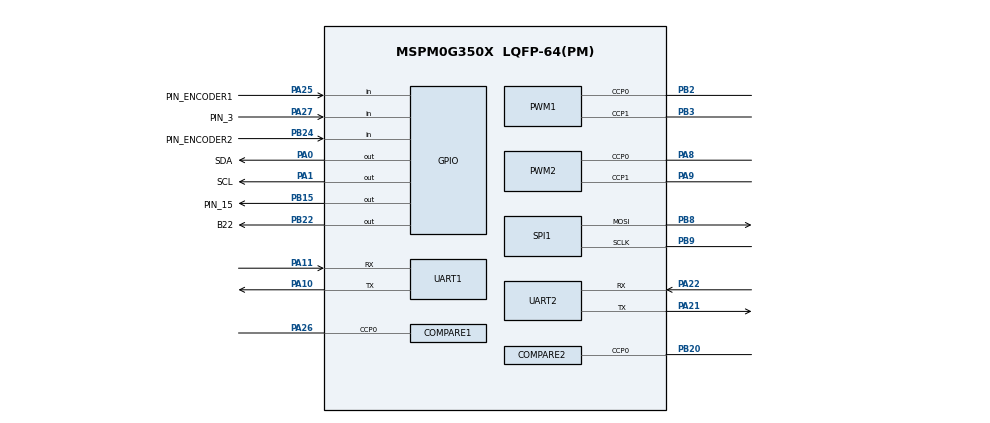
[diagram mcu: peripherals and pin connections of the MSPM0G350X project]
/**
 * @cliArgs --device "MSPM0G350X" --part "Default" --package "LQFP-64(PM)" --product "mspm0_sdk@2.02.00.05"
 * @versions {"tool":"1.21.1+3772"}
 */

/**
 * Import the modules used in this configuration.
 */
const COMPARE  = scripting.addModule("/ti/driverlib/COMPARE", {}, false);
const COMPARE1 = COMPARE.addInstance();
const COMPARE2 = COMPARE.addInstance();
const DMA      = scripting.addModule("/ti/driverlib/DMA");
const GPIO     = scripting.addModule("/ti/driverlib/GPIO", {}, false);
const GPIO1    = GPIO.addInstance();
const GPIO2    = GPIO.addInstance();
const GPIO3    = GPIO.addInstance();
const GPIO4    = GPIO.addInstance();
const GPIO5    = GPIO.addInstance();
const GPIO6    = GPIO.addInstance();
const GPIO7    = GPIO.addInstance();
const GPIO8    = GPIO.addInstance();
const PWM      = scripting.addModule("/ti/driverlib/PWM", {}, false);
const PWM1     = PWM.addInstance();
const PWM2     = PWM.addInstance();
const SPI      = scripting.addModule("/ti/driverlib/SPI", {}, false);
const SPI1     = SPI.addInstance();
const SYSCTL   = scripting.addModule("/ti/driverlib/SYSCTL");
const SYSTICK  = scripting.addModule("/ti/driverlib/SYSTICK");
const TIMER    = scripting.addModule("/ti/driverlib/TIMER", {}, false);
const TIMER1   = TIMER.addInstance();
const UART     = scripting.addModule("/ti/driverlib/UART", {}, false);
const UART1    = UART.addInstance();
const UART2    = UART.addInstance();

/**
 * Write custom configuration values to the imported modules.
 */
const divider9       = system.clockTree["UDIV"];
divider9.divideValue = 2;

const gate7  = system.clockTree["MFCLKGATE"];
gate7.enable = true;

const multiplier2         = system.clockTree["PLL_QDIV"];
multiplier2.multiplyValue = 4;

const mux4       = system.clockTree["EXHFMUX"];
mux4.inputSelect = "EXHFMUX_XTAL";

const mux8       = system.clockTree["HSCLKMUX"];
mux8.inputSelect = "HSCLKMUX_SYSPLL0";

const mux12       = system.clockTree["SYSPLLMUX"];
mux12.inputSelect = "zSYSPLLMUX_HFCLK";

const pinFunction4     = system.clockTree["HFXT"];
pinFunction4.enable    = true;
pinFunction4.inputFreq = 40;

COMPARE1.$name                              = "ENCODER1";
COMPARE1.timerPeriod                        = 65536;
COMPARE1.timerStartTimer                    = true;
COMPARE1.edgeDetection                      = "EDGE";
COMPARE1.compareMode                        = "EDGE_COUNT_UP";
COMPARE1.filterPeriod                       = "PER_8";
COMPARE1.timerClkSrc                        = "MFCLK";
COMPARE1.peripheral.$assign                 = "TIMG8";
COMPARE1.peripheral.ccp0Pin.$assign         = "PA26";
COMPARE1.ccp0PinConfig.hideOutputInversion  = scripting.forceWrite(false);
COMPARE1.ccp0PinConfig.onlyInternalResistor = scripting.forceWrite(false);
COMPARE1.ccp0PinConfig.passedPeripheralType = scripting.forceWrite("Digital");
COMPARE1.ccp0PinConfig.$name                = "ti_driverlib_gpio_GPIOPinGeneric12";
COMPARE1.ccp0PinConfig.internalResistor     = "PULL_DOWN";

const Board = scripting.addModule("/ti/driverlib/Board", {}, false);

COMPARE2.timerPeriod                        = 65536;
COMPARE2.timerStartTimer                    = true;
COMPARE2.edgeDetection                      = "EDGE";
COMPARE2.compareMode                        = "EDGE_COUNT_UP";
COMPARE2.filterPeriod                       = "PER_8";
COMPARE2.$name                              = "ENCODER2";
COMPARE2.timerClkSrc                        = "MFCLK";
COMPARE2.timerClkDiv                        = 4;
COMPARE2.peripheral.$assign                 = "TIMG12";
COMPARE2.peripheral.ccp0Pin.$assign         = "PB20";
COMPARE2.ccp0PinConfig.hideOutputInversion  = scripting.forceWrite(false);
COMPARE2.ccp0PinConfig.onlyInternalResistor = scripting.forceWrite(false);
COMPARE2.ccp0PinConfig.passedPeripheralType = scripting.forceWrite("Digital");
COMPARE2.ccp0PinConfig.$name                = "ti_driverlib_gpio_GPIOPinGeneric12_COPY";
COMPARE2.ccp0PinConfig.internalResistor     = "PULL_DOWN";

GPIO1.$name                               = "KEY";
GPIO1.port                                = "PORTB";
GPIO1.associatedPins.create(4);
GPIO1.associatedPins[0].direction         = "INPUT";
GPIO1.associatedPins[0].ioStructure       = "SD";
GPIO1.associatedPins[0].internalResistor  = "PULL_UP";
GPIO1.associatedPins[0].assignedPin       = "21";
GPIO1.associatedPins[0].polarity          = "FALL";
GPIO1.associatedPins[0].interruptEn       = true;
GPIO1.associatedPins[0].interruptPriority = "0";
GPIO1.associatedPins[0].$name             = "up";
GPIO1.associatedPins[1].direction         = "INPUT";
GPIO1.associatedPins[1].ioStructure       = "SD";
GPIO1.associatedPins[1].internalResistor  = "PULL_UP";
GPIO1.associatedPins[1].assignedPin       = "19";
GPIO1.associatedPins[1].$name             = "down";
GPIO1.associatedPins[2].direction         = "INPUT";
GPIO1.associatedPins[2].ioStructure       = "SD";
GPIO1.associatedPins[2].internalResistor  = "PULL_UP";
GPIO1.associatedPins[2].assignedPin       = "18";
GPIO1.associatedPins[2].$name             = "left";
GPIO1.associatedPins[3].direction         = "INPUT";
GPIO1.associatedPins[3].ioStructure       = "SD";
GPIO1.associatedPins[3].internalResistor  = "PULL_UP";
GPIO1.associatedPins[3].assignedPin       = "17";
GPIO1.associatedPins[3].$name             = "right";

GPIO2.$name                              = "LED";
GPIO2.port                               = "PORTB";
GPIO2.associatedPins[0].$name            = "B22";
GPIO2.associatedPins[0].ioStructure      = "SD";
GPIO2.associatedPins[0].internalResistor = "PULL_DOWN";
GPIO2.associatedPins[0].assignedPin      = "22";
GPIO2.associatedPins[0].pin.$assign      = "PB22";

GPIO3.$name                          = "LCD";
GPIO3.associatedPins.create(4);
GPIO3.associatedPins[0].ioStructure  = "SD";
GPIO3.associatedPins[0].initialValue = "SET";
GPIO3.associatedPins[0].$name        = "RES";
GPIO3.associatedPins[0].assignedPort = "PORTB";
GPIO3.associatedPins[0].assignedPin  = "10";
GPIO3.associatedPins[1].initialValue = "SET";
GPIO3.associatedPins[1].ioStructure  = "SD";
GPIO3.associatedPins[1].$name        = "DC";
GPIO3.associatedPins[1].assignedPort = "PORTB";
GPIO3.associatedPins[1].assignedPin  = "11";
GPIO3.associatedPins[2].initialValue = "SET";
GPIO3.associatedPins[2].ioStructure  = "SD";
GPIO3.associatedPins[2].$name        = "CS";
GPIO3.associatedPins[2].assignedPort = "PORTB";
GPIO3.associatedPins[2].assignedPin  = "14";
GPIO3.associatedPins[3].ioStructure  = "SD";
GPIO3.associatedPins[3].initialValue = "SET";
GPIO3.associatedPins[3].$name        = "BLK";
GPIO3.associatedPins[3].assignedPort = "PORTB";
GPIO3.associatedPins[3].assignedPin  = "26";

GPIO4.$name                          = "Gray_Address";
GPIO4.associatedPins.create(4);
GPIO4.associatedPins[0].$name        = "PIN_0";
GPIO4.associatedPins[0].assignedPort = "PORTA";
GPIO4.associatedPins[0].assignedPin  = "17";
GPIO4.associatedPins[0].direction    = "INPUT";
GPIO4.associatedPins[1].$name        = "PIN_1";
GPIO4.associatedPins[1].assignedPort = "PORTA";
GPIO4.associatedPins[1].assignedPin  = "16";
GPIO4.associatedPins[1].direction    = "INPUT";
GPIO4.associatedPins[2].$name        = "PIN_2";
GPIO4.associatedPins[2].assignedPort = "PORTA";
GPIO4.associatedPins[2].assignedPin  = "15";
GPIO4.associatedPins[2].direction    = "INPUT";
GPIO4.associatedPins[3].$name        = "PIN_3";
GPIO4.associatedPins[3].assignedPort = "PORTA";
GPIO4.associatedPins[3].assignedPin  = "27";
GPIO4.associatedPins[3].direction    = "INPUT";
GPIO4.associatedPins[3].pin.$assign  = "PA27";

GPIO5.$name                          = "IIC_Software";
GPIO5.associatedPins.create(2);
GPIO5.associatedPins[0].$name        = "SDA";
GPIO5.associatedPins[0].initialValue = "SET";
GPIO5.associatedPins[0].ioStructure  = "OD";
GPIO5.associatedPins[0].assignedPort = "PORTA";
GPIO5.associatedPins[0].assignedPin  = "0";
GPIO5.associatedPins[0].pin.$assign  = "PA0";
GPIO5.associatedPins[1].$name        = "SCL";
GPIO5.associatedPins[1].initialValue = "SET";
GPIO5.associatedPins[1].ioStructure  = "OD";
GPIO5.associatedPins[1].assignedPort = "PORTA";
GPIO5.associatedPins[1].assignedPin  = "1";
GPIO5.associatedPins[1].pin.$assign  = "PA1";

GPIO6.$name                               = "ENCODER1_DIR";
GPIO6.port                                = "PORTA";
GPIO6.associatedPins[0].$name             = "PIN_ENCODER1";
GPIO6.associatedPins[0].direction         = "INPUT";
GPIO6.associatedPins[0].interruptEn       = true;
GPIO6.associatedPins[0].interruptPriority = "1";
GPIO6.associatedPins[0].polarity          = "RISE_FALL";
GPIO6.associatedPins[0].assignedPin       = "25";
GPIO6.associatedPins[0].pin.$assign       = "PA25";

GPIO7.$name                               = "ENCODER2_DIR";
GPIO7.port                                = "PORTB";
GPIO7.associatedPins[0].$name             = "PIN_ENCODER2";
GPIO7.associatedPins[0].direction         = "INPUT";
GPIO7.associatedPins[0].interruptEn       = true;
GPIO7.associatedPins[0].polarity          = "RISE_FALL";
GPIO7.associatedPins[0].interruptPriority = "1";
GPIO7.associatedPins[0].assignedPin       = "24";
GPIO7.associatedPins[0].pin.$assign       = "PB24";

GPIO8.$name                              = "GPIO_MOS";
GPIO8.port                               = "PORTB";
GPIO8.associatedPins[0].$name            = "PIN_15";
GPIO8.associatedPins[0].internalResistor = "PULL_DOWN";
GPIO8.associatedPins[0].assignedPin      = "15";
GPIO8.associatedPins[0].pin.$assign      = "PB15";

PWM1.$name                      = "PWM_0";
PWM1.timerStartTimer            = true;
PWM1.pwmMode                    = "EDGE_ALIGN_UP";
PWM1.timerCount                 = 8000;
PWM1.peripheral.$assign         = "TIMA1";
PWM1.peripheral.ccp0Pin.$assign = "PB2";
PWM1.peripheral.ccp1Pin.$assign = "PB3";
PWM1.PWM_CHANNEL_0.$name        = "ti_driverlib_pwm_PWMTimerCC0";
PWM1.PWM_CHANNEL_1.$name        = "ti_driverlib_pwm_PWMTimerCC1";
PWM1.ccp0PinConfig.$name        = "PWM";
PWM1.ccp1PinConfig.$name        = "P";

PWM2.$name                      = "PWM_1";
PWM2.timerCount                 = 8000;
PWM2.timerStartTimer            = true;
PWM2.pwmMode                    = "EDGE_ALIGN_UP";
PWM2.peripheral.$assign         = "TIMA0";
PWM2.peripheral.ccp0Pin.$assign = "PA8";
PWM2.peripheral.ccp1Pin.$assign = "PA9";
PWM2.PWM_CHANNEL_0.$name        = "ti_driverlib_pwm_PWMTimerCC2";
PWM2.PWM_CHANNEL_1.$name        = "ti_driverlib_pwm_PWMTimerCC3";
PWM2.ccp0PinConfig.$name        = "PW";
PWM2.ccp1PinConfig.$name        = "PWM_";

SPI1.direction                          = "PICO";
SPI1.frameFormat                        = "MOTO3";
SPI1.targetBitRate                      = 16000000;
SPI1.$name                              = "SPI_LCD";
SPI1.peripheral.$assign                 = "SPI1";
SPI1.peripheral.sclkPin.$assign         = "PB9";
SPI1.peripheral.mosiPin.$assign         = "PB8";
SPI1.sclkPinConfig.direction            = scripting.forceWrite("OUTPUT");
SPI1.sclkPinConfig.onlyInternalResistor = scripting.forceWrite(false);
SPI1.sclkPinConfig.passedPeripheralType = scripting.forceWrite("Digital");
SPI1.sclkPinConfig.$name                = "ti_driverlib_gpio_GPIOPinGeneric4";
SPI1.mosiPinConfig.direction            = scripting.forceWrite("OUTPUT");
SPI1.mosiPinConfig.hideOutputInversion  = scripting.forceWrite(false);
SPI1.mosiPinConfig.onlyInternalResistor = scripting.forceWrite(false);
SPI1.mosiPinConfig.passedPeripheralType = scripting.forceWrite("Digital");
SPI1.mosiPinConfig.$name                = "ti_driverlib_gpio_GPIOPinGeneric5";

SYSCTL.forceDefaultClkConfig = true;
SYSCTL.clockTreeEn           = true;

SYSTICK.periodEnable      = true;
SYSTICK.systickEnable     = true;
SYSTICK.interruptPriority = "0";
SYSTICK.period            = 32;

TIMER1.timerClkDiv        = 4;
TIMER1.timerClkPrescale   = 80;
TIMER1.timerPeriod        = "100us";
TIMER1.timerStartTimer    = true;
TIMER1.timerMode          = "PERIODIC";
TIMER1.interrupts         = ["ZERO"];
TIMER1.$name              = "TIMER_1";
TIMER1.peripheral.$assign = "TIMG7";

UART1.$name                    = "UART_0";
UART1.uartClkSrc               = "MFCLK";
UART1.enabledInterrupts        = ["RX"];
UART1.targetBaudRate           = 115200;
UART1.peripheral.$assign       = "UART0";
UART1.peripheral.rxPin.$assign = "PA11";
UART1.peripheral.txPin.$assign = "PA10";
UART1.txPinConfig.$name        = "ti_driverlib_gpio_GPIOPinGeneric0";
UART1.rxPinConfig.$name        = "ti_driverlib_gpio_GPIOPinGeneric1";

UART2.targetBaudRate                   = 115200;
UART2.enabledInterrupts                = ["RX"];
UART2.interruptPriority                = "2";
UART2.$name                            = "UART_ppr";
UART2.peripheral.$assign               = "UART2";
UART2.peripheral.rxPin.$assign         = "PA22";
UART2.peripheral.txPin.$assign         = "PA21";
UART2.txPinConfig.direction            = scripting.forceWrite("OUTPUT");
UART2.txPinConfig.hideOutputInversion  = scripting.forceWrite(false);
UART2.txPinConfig.onlyInternalResistor = scripting.forceWrite(false);
UART2.txPinConfig.passedPeripheralType = scripting.forceWrite("Digital");
UART2.txPinConfig.$name                = "ti_driverlib_gpio_GPIOPinGeneric7";
UART2.rxPinConfig.hideOutputInversion  = scripting.forceWrite(false);
UART2.rxPinConfig.onlyInternalResistor = scripting.forceWrite(false);
UART2.rxPinConfig.passedPeripheralType = scripting.forceWrite("Digital");
UART2.rxPinConfig.$name                = "ti_driverlib_gpio_GPIOPinGeneric9";

/**
 * Pinmux solution for unlocked pins/peripherals. This ensures that minor changes to the automatic solver in a future
 * version of the tool will not impact the pinmux you originally saw.  These lines can be completely deleted in order to
 * re-solve from scratch.
 */
pinFunction4.peripheral.$suggestSolution           = "SYSCTL";
pinFunction4.peripheral.hfxInPin.$suggestSolution  = "PA5";
pinFunction4.peripheral.hfxOutPin.$suggestSolution = "PA6";
Board.peripheral.$suggestSolution                  = "DEBUGSS";
Board.peripheral.swclkPin.$suggestSolution         = "PA20";
Board.peripheral.swdioPin.$suggestSolution         = "PA19";
GPIO1.associatedPins[0].pin.$suggestSolution       = "PB21";
GPIO1.associatedPins[1].pin.$suggestSolution       = "PB19";
GPIO1.associatedPins[2].pin.$suggestSolution       = "PB18";
GPIO1.associatedPins[3].pin.$suggestSolution       = "PB17";
GPIO3.associatedPins[0].pin.$suggestSolution       = "PB10";
GPIO3.associatedPins[1].pin.$suggestSolution       = "PB11";
GPIO3.associatedPins[2].pin.$suggestSolution       = "PB14";
GPIO3.associatedPins[3].pin.$suggestSolution       = "PB26";
GPIO4.associatedPins[0].pin.$suggestSolution       = "PA17";
GPIO4.associatedPins[1].pin.$suggestSolution       = "PA16";
GPIO4.associatedPins[2].pin.$suggestSolution       = "PA15";
